# dm64lc_cslr_hist_001 register map
Vendor: Texas Instruments
Peripheral module from a debugger description file.
Registers are 32-bit, access not given, reset 0x0 unless marked. A register's access mark holds for its fields unless they carry their own. Offsets are as the file gives them; lines under a group give offsets from that group; [hi:lo] are bit positions; {n}, {i} and the like mark numbered series; 'fields as' and 'values as' point back to an identical list; <NAME> marks a mode.

## HIST — histogram (spec version: 1.00.w.11)
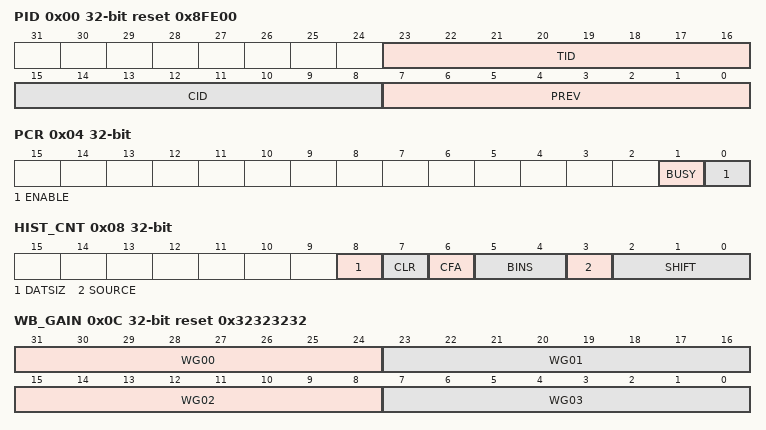
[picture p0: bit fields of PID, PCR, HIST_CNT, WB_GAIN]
0x00 PID reset 0x8FE00 — Peripheral Revision and Class Information
  [23:16] TID ro — Peripheral Identification Histogram module
  [15:8] CID ro — Class Identification Video processing front end
  [7:0] PREV ro — Peripheral Revision Number Initial Revision
0x04 PCR — Peripheral Control Register
  [1] BUSY ro — Busy bit
    0=NOTBUSY (Histogram is not busy); 1=BUSY (Histogram is busy)
  [0] ENABLE rw
    0=DISABLE (Disable module); 1=ENABLE (Enable module)
0x08 HIST_CNT — Histogram control bits
  [8] DATSIZ rw — Input data width
    0=9TO14_BITS ((9-14)-bits); 1=8BITS
  [7] CLR rw — Clear Data after read
    0=NOCLEAR_AFTER_READ (Don't clear data after read); 1=CLEAR_AFTER_READ (Clear data after read)
  [6] CFA rw — CFA pattern
    0=2D_2X2_CONVENTIONAL (2D (2 x 2) conventional pattern); 1=RSV (Reserved)
  [5:4] BINS rw — No of bins per histogram
    0=32BINS (32 bins - Regions 0, 1, 2, and 3 are active); 1=64BINS (64 bins - Regions 0, 1, 2, and 3 are active); 2=128BINS (128 bins - only Regions 0 and 1 are active); 3=256BINS (256 bins - only Region 0 is active)
  [3] SOURCE rw — Input Source: CCDC or SDRAM
    0=CCDC; 1=SDRAM
  [2:0] SHIFT rw — No of bits to right shift data before accessing bins (0-7)
0x0C WB_GAIN rw reset 0x32323232 — White/channel balance settings
  [31-8n:24-8n] WG{n:02} (n=0..3) — White Balance Gain {n:02} It is set within the range of x0~x7.96875(7+31/32). The decimal point is located between WG{n:02}[5] and WG{n:02}[4]
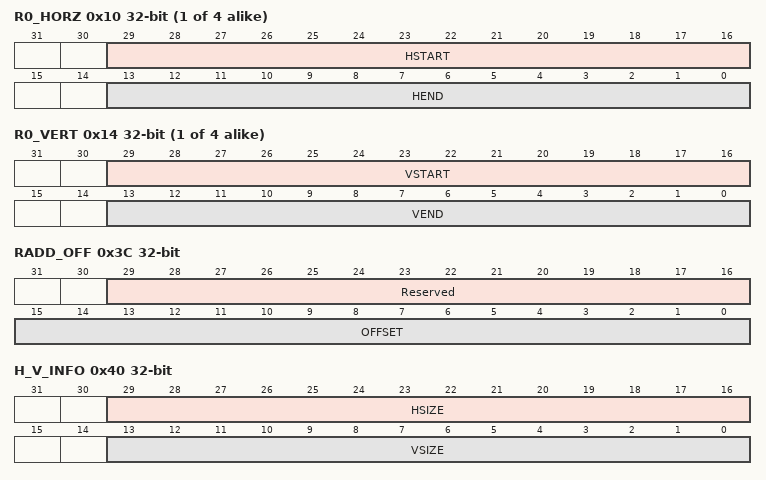
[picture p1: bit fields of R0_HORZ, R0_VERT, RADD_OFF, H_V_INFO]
{0x10+8i} R{i}_HORZ (i=0..3) — Region {i} Horizontal information
  [29:16] HSTART rw — Horizontal start location for region {i}
  [13:0] HEND rw — Horizontal end for region {i} If the "end" is programmed as the same value of "start", then the region size is treated as 0 In all cases, the total number of pixels processed is "End - Start + 1". Therefore, the minimum region dimension is at least 2
{0x14+8i} R{i}_VERT (i=0..3) — Region {i} Vertical information
  [29:16] VSTART rw — Vertical start location for region {i}
  [13:0] VEND rw — Vertical end for region {i} If the "end" is programmed as the same value of "start", then the region size is treated as 0 In all cases, the total number of pixels processed is "End - Start + 1". Therefore, the minimum region dimension is at least 2
0x30 HIST_ADDR — Histogram address for data to be read
  [9:0] ADDR rw — Address of histogram entry (note that each entry is 20-bit wide)
0x34 HIST_DATA — Histogram data that is read from the memory
  [19:0] RDATA rw
0x38 RADD rw — Read address from SDRAM/DDRAM
  [31:0] RADD — Read Address Specifies the address on VBUSM dma port that should be initially read The 5 LSB are always treated as zeroes - the starting address must be aligned on a 32-byte boundary * This field can be altered even when the histogram is busy. Change will take place only for the next frame. However, note that reading this register will always give the latest value.
0x3C RADD_OFF — Read address offset for each line in the SDRAM/DDRAM
  [29:16] Reserved — (access N)
  [15:0] OFFSET rw — Offset for each line in the SDRAM/DDRAM The 5 LSB are treated as zeroes - the offset must be aligned on a 32-byte boundary * This field can be altered even when the histogram is busy. Change will take place only for the next frame. However, note that reading this register will always give the latest value.
0x40 H_V_INFO — Horz/vert number of pixels when data is read from SDRAM/DDRAM
  [29:16] HSIZE rw — Number of horizontal pixels when the input data source is the SDRAM/DDRAM
  [13:0] VSIZE rw — Number of vertical lines when the input data source is the SDRAM/DDRAM
